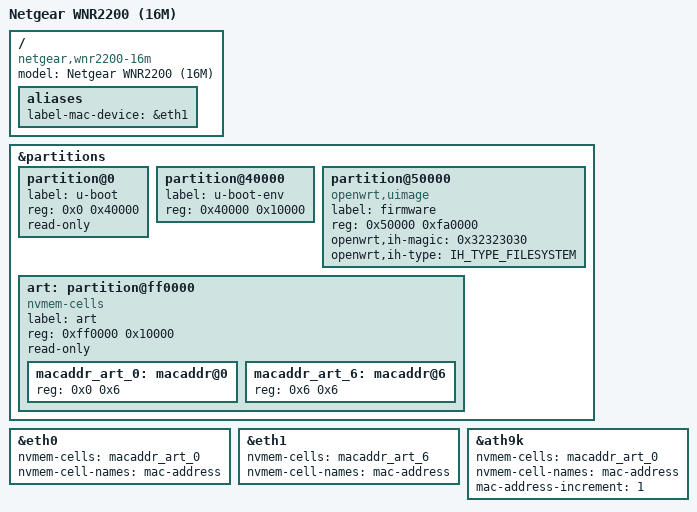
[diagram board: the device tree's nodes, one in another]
// SPDX-License-Identifier: GPL-2.0-or-later OR MIT

#include "ar7241_netgear_wnr2200.dtsi"

/ {
	compatible = "netgear,wnr2200-16m", "qca,ar7241";
	model = "Netgear WNR2200 (16M)";

	aliases {
		label-mac-device = &eth1;
	};
};

&partitions {
	partition@0 {
		label = "u-boot";
		reg = <0x0 0x40000>;
		read-only;
	};

	partition@40000 {
		label = "u-boot-env";
		reg = <0x40000 0x10000>;
	};

	partition@50000 {
		label = "firmware";
		reg = <0x50000 0xfa0000>;
		compatible = "openwrt,uimage", "denx,uimage";
		openwrt,ih-magic = <0x32323030>;
		openwrt,ih-type = <IH_TYPE_FILESYSTEM>;
	};

	art: partition@ff0000 {
		label = "art";
		reg = <0xff0000 0x10000>;
		read-only;
	};
};

&eth0 {
	nvmem-cells = <&macaddr_art_0>;
	nvmem-cell-names = "mac-address";
};

&eth1 {
	nvmem-cells = <&macaddr_art_6>;
	nvmem-cell-names = "mac-address";
};

&ath9k {
	nvmem-cells = <&macaddr_art_0>;
	nvmem-cell-names = "mac-address";
	mac-address-increment = <1>;
};

&art {
	compatible = "nvmem-cells";
	#address-cells = <1>;
	#size-cells = <1>;

	macaddr_art_0: macaddr@0 {
		reg = <0x0 0x6>;
	};

	macaddr_art_6: macaddr@6 {
		reg = <0x6 0x6>;
	};
};
